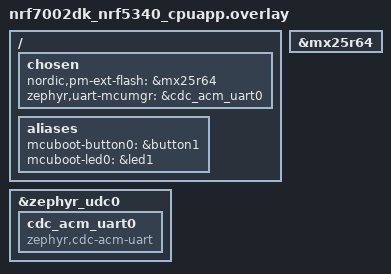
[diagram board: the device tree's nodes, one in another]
/*
 * Copyright (c) 2023 Nordic Semiconductor ASA
 *
 * SPDX-License-Identifier: LicenseRef-Nordic-5-Clause
 */
&mx25r64 {
	status = "okay";
};

/ {
	chosen {
		/delete-property/ zephyr,ipc_shm;
		nordic,pm-ext-flash = &mx25r64;
	};
};

/ {
  aliases {
		mcuboot-button0 = &button1;
		mcuboot-led0 = &led1;
  };
};

/* Configure CDC ACM for serial recovery over USB */
&zephyr_udc0 {
	cdc_acm_uart0: cdc_acm_uart0 {
		compatible = "zephyr,cdc-acm-uart";
	};
};

/* Redirect MCUmgr to USB CDC so UART console can stay enabled for logs */
/ {
	chosen {
		zephyr,uart-mcumgr = &cdc_acm_uart0;
	};
};
